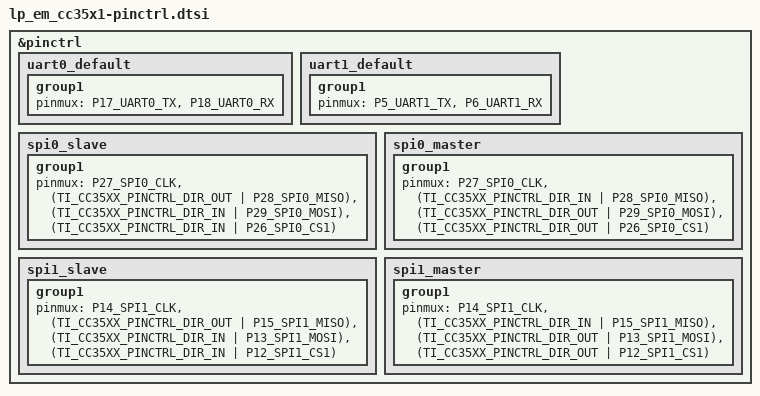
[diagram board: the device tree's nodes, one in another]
/*
 * Copyright (c) 2025 Conclusive Engineering Sp. z o.o.
 *
 * SPDX-License-Identifier: Apache-2.0
 */

#include <zephyr/dt-bindings/pinctrl/ti-cc35xx-pinctrl.h>

&pinctrl {
	uart0_default: uart0_default {
		group1 {
			pinmux = <P17_UART0_TX>, <P18_UART0_RX>;
		};
	};
	uart1_default: uart1_default {
		group1 {
			pinmux = <P5_UART1_TX>, <P6_UART1_RX>;
		};
	};

	spi0_slave: spi0_slave {
		group1 {
			pinmux = <P27_SPI0_CLK>,
				<(TI_CC35XX_PINCTRL_DIR_OUT | P28_SPI0_MISO)>,
				<(TI_CC35XX_PINCTRL_DIR_IN  | P29_SPI0_MOSI)>,
				<(TI_CC35XX_PINCTRL_DIR_IN  | P26_SPI0_CS1)>;
		};
	};
	spi0_master: spi0_master {
		group1 {
			pinmux = <P27_SPI0_CLK>,
				<(TI_CC35XX_PINCTRL_DIR_IN  | P28_SPI0_MISO)>,
				<(TI_CC35XX_PINCTRL_DIR_OUT | P29_SPI0_MOSI)>,
				<(TI_CC35XX_PINCTRL_DIR_OUT | P26_SPI0_CS1)>;
		};
	};

	spi1_slave: spi1_slave {
		group1 {
			pinmux = <P14_SPI1_CLK>,
				<(TI_CC35XX_PINCTRL_DIR_OUT | P15_SPI1_MISO)>,
				<(TI_CC35XX_PINCTRL_DIR_IN  | P13_SPI1_MOSI)>,
				<(TI_CC35XX_PINCTRL_DIR_IN  | P12_SPI1_CS1)>;
		};
	};
	spi1_master: spi1_master {
		group1 {
			pinmux = <P14_SPI1_CLK>,
				<(TI_CC35XX_PINCTRL_DIR_IN  | P15_SPI1_MISO)>,
				<(TI_CC35XX_PINCTRL_DIR_OUT | P13_SPI1_MOSI)>,
				<(TI_CC35XX_PINCTRL_DIR_OUT | P12_SPI1_CS1)>;
		};
	};
};
